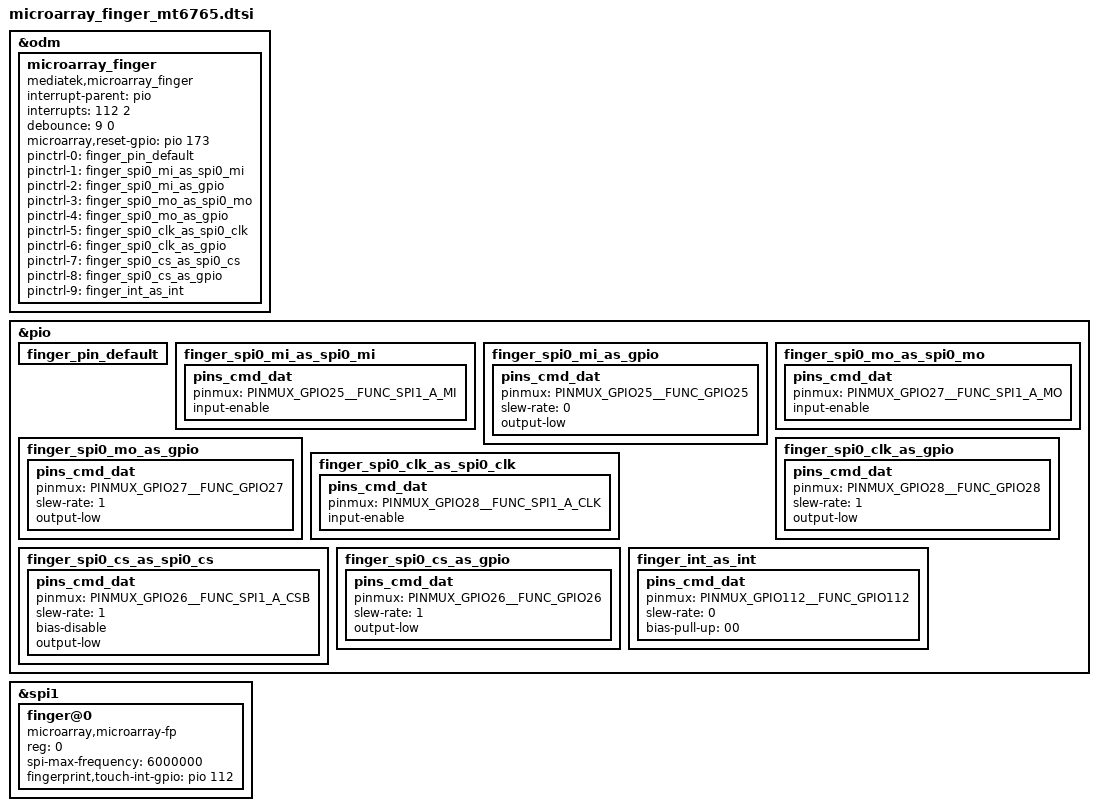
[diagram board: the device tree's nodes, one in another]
/* microarray fingerprint ctrl start */

&odm{
	microarray_finger: microarray_finger {
		compatible = "mediatek,microarray_finger";
	};
};

&microarray_finger {
		interrupt-parent = <&pio>;
		interrupts = <112 2>;
		debounce = <9 0>;

		microarray,reset-gpio=<&pio 173 0>;

		pinctrl-names = "default"/*, "finger_power_en1", "finger_power_en0","finger_power_18v_en1","finger_power_18v_en0"*/,"finger_spi0_mi_as_spi0_mi","finger_spi0_mi_as_gpio","finger_spi0_mo_as_spi0_mo","finger_spi0_mo_as_gpio","finger_spi0_clk_as_spi0_clk","finger_spi0_clk_as_gpio","finger_spi0_cs_as_spi0_cs","finger_spi0_cs_as_gpio", "finger_int_as_int";
		pinctrl-0 = <&finger_pin_default>;
		/*
		pinctrl-1 = <&finger_power_en1>;
		pinctrl-2 = <&finger_power_en0>;
		pinctrl-1 = <&finger_power_18v_en1>;
		pinctrl-2 = <&finger_power_18v_en0>;
		*/
		pinctrl-1 = <&finger_spi0_mi_as_spi0_mi>;
		pinctrl-2 = <&finger_spi0_mi_as_gpio>;
		pinctrl-3 = <&finger_spi0_mo_as_spi0_mo>;
		pinctrl-4 = <&finger_spi0_mo_as_gpio>;
		pinctrl-5 = <&finger_spi0_clk_as_spi0_clk>;
		pinctrl-6 = <&finger_spi0_clk_as_gpio>;
		pinctrl-7 = <&finger_spi0_cs_as_spi0_cs>;
		pinctrl-8 = <&finger_spi0_cs_as_gpio>;
		pinctrl-9 = <&finger_int_as_int>;
		status = "okay";
};

&pio {
	finger_pin_default: finger_pin_default {
	};
	/*
	finger_power_en1: finger_power_en1 {
		pins_cmd_dat {
			pinmux = <PINMUX_GPIO24__FUNC_GPIO24>;
			slew-rate = <1>;
			output-high;
		};
	};
	finger_power_en0: finger_power_en0 {
		pins_cmd_dat {
			pinmux = <PINMUX_GPIO24__FUNC_GPIO24>;
			slew-rate = <1>;
			output-low;
		};
	};
	
	finger_power_18v_en1: finger_power_18v_en1 {
		pins_cmd_dat {
			pinmux = <PINMUX_GPIO173__FUNC_GPIO173>;
			slew-rate = <1>;
			output-high;
		};
	};
	finger_power_18v_en0: finger_power_18v_en0 {
		pins_cmd_dat {
			pinmux = <PINMUX_GPIO173__FUNC_GPIO173>;
			slew-rate = <1>;
			output-low;
		};
	};
*/
	finger_spi0_mi_as_spi0_mi: finger_spi0_mi_as_spi0_mi {
		pins_cmd_dat {
			pinmux = <PINMUX_GPIO25__FUNC_SPI1_A_MI>;
			input-enable;
		};
	};
	finger_spi0_mi_as_gpio: finger_spi0_mi_as_gpio {
		pins_cmd_dat {
			pinmux = <PINMUX_GPIO25__FUNC_GPIO25>;
			slew-rate = <0>;
			output-low;
		};
	};
	finger_spi0_mo_as_spi0_mo: finger_spi0_mo_as_spi0_mo {
		pins_cmd_dat {
			pinmux = <PINMUX_GPIO27__FUNC_SPI1_A_MO>;
			input-enable;
		};
	};
	finger_spi0_mo_as_gpio: finger_spi0_mo_as_gpio {
		pins_cmd_dat {
			pinmux = <PINMUX_GPIO27__FUNC_GPIO27>;
			slew-rate = <1>;
			output-low;
		};
	};
	finger_spi0_clk_as_spi0_clk: finger_spi0_clk_as_spi0_clk {
		pins_cmd_dat {
			pinmux = <PINMUX_GPIO28__FUNC_SPI1_A_CLK>;
			input-enable;
		};
	};
	finger_spi0_clk_as_gpio: finger_spi0_clk_as_gpio {
		pins_cmd_dat {
			pinmux = <PINMUX_GPIO28__FUNC_GPIO28>;
			slew-rate = <1>;
			output-low;
		};
	};
	finger_spi0_cs_as_spi0_cs: finger_spi0_cs_as_spi0_cs {
		pins_cmd_dat {
			pinmux = <PINMUX_GPIO26__FUNC_SPI1_A_CSB>;
			slew-rate = <1>;
			bias-disable;
			output-low;
		};
	};
	finger_spi0_cs_as_gpio: finger_spi0_cs_as_gpio {
		pins_cmd_dat {
			pinmux = <PINMUX_GPIO26__FUNC_GPIO26>;
			slew-rate = <1>;
			output-low;
		};
	};
	finger_int_as_int: finger_int_as_int {
		pins_cmd_dat {
			pinmux = <PINMUX_GPIO112__FUNC_GPIO112>;
			slew-rate = <0>;
			bias-pull-up = <00>;
		};
	};

};

&spi1 {
	#address-cells = <1>;     
	#size-cells = <0>;
 
    	finger@0 {
       		compatible = "microarray,microarray-fp";
       		reg = <0>;
       		spi-max-frequency = <6000000>;	
        	fingerprint,touch-int-gpio = <&pio 112 0>;
		
       		status = "okay";
    	}; 
};
/* microarray fingerprint ctrl end */
